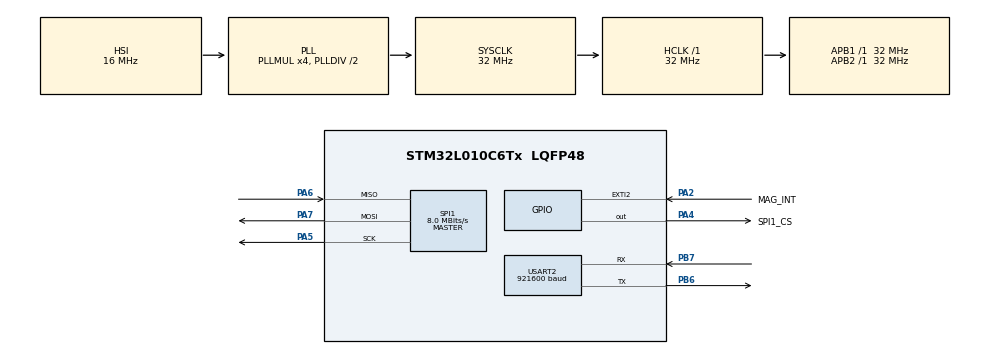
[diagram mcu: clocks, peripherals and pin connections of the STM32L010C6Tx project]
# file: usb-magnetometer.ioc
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Dma.Request0=USART2_RX
Dma.Request1=USART2_TX
Dma.USART2_RX.0.Direction=DMA_PERIPH_TO_MEMORY
Dma.USART2_RX.0.Instance=DMA1_Channel5
Dma.USART2_RX.0.MemDataAlignment=DMA_MDATAALIGN_BYTE
Dma.USART2_RX.0.MemInc=DMA_MINC_ENABLE
Dma.USART2_RX.0.Mode=DMA_NORMAL
Dma.USART2_RX.0.PeriphDataAlignment=DMA_PDATAALIGN_BYTE
Dma.USART2_RX.0.PeriphInc=DMA_PINC_DISABLE
Dma.USART2_RX.0.Priority=DMA_PRIORITY_MEDIUM
Dma.USART2_TX.1.Direction=DMA_MEMORY_TO_PERIPH
Dma.USART2_TX.1.Instance=DMA1_Channel4
Dma.USART2_TX.1.MemDataAlignment=DMA_MDATAALIGN_BYTE
Dma.USART2_TX.1.MemInc=DMA_MINC_ENABLE
Dma.USART2_TX.1.Mode=DMA_NORMAL
Dma.USART2_TX.1.PeriphDataAlignment=DMA_PDATAALIGN_BYTE
Dma.USART2_TX.1.PeriphInc=DMA_PINC_DISABLE
Dma.USART2_TX.1.Priority=DMA_PRIORITY_MEDIUM
Mcu.Family=STM32L0
Mcu.Name=STM32L010C6Tx
Mcu.Package=LQFP48
NVIC.DMA1_Channel4_5_6_7_IRQn=true\:0\:0\:false\:true\:true\:1\:false\:true\:true
NVIC.EXTI2_3_IRQn=true\:0\:0\:false\:true\:true\:3\:true\:true\:false
NVIC.USART2_IRQn=true\:0\:0\:false\:true\:true\:2\:true\:true\:true
PA2.GPIO_Label=MAG_INT
PA2.GPIO_ModeDefaultEXTI=GPIO_MODE_IT_FALLING
PA2.GPIO_PuPd=GPIO_NOPULL
PA2.Signal=GPXTI2
PA4.GPIO_Label=SPI1_CS
PA4.GPIO_Speed=GPIO_SPEED_FREQ_VERY_HIGH
PA4.PinState=GPIO_PIN_SET
PA4.Signal=GPIO_Output
PA5.Mode=Full_Duplex_Master
PA5.Signal=SPI1_SCK
PA6.Mode=Full_Duplex_Master
PA6.Signal=SPI1_MISO
PA7.Mode=Full_Duplex_Master
PA7.Signal=SPI1_MOSI
PB6.Mode=Asynchronous
PB6.Signal=USART2_TX
PB7.Mode=Asynchronous
PB7.Signal=USART2_RX
ProjectManager.HeapSize=0x000
ProjectManager.StackSize=0x200
ProjectManager.TargetToolchain=Makefile
RCC.AHBFreq_Value=32000000
RCC.APB1Freq_Value=32000000
RCC.APB1TimFreq_Value=32000000
RCC.APB2Freq_Value=32000000
RCC.APB2TimFreq_Value=32000000
RCC.HCLKFreq_Value=32000000
RCC.HSE_VALUE=24000000
RCC.HSI16_VALUE=16000000
RCC.HSI_VALUE=16000000
RCC.LSE_VALUE=32768
RCC.MSI_VALUE=2097000
RCC.PLLMUL=RCC_PLLMUL_4
RCC.SYSCLKFreq_VALUE=32000000
RCC.SYSCLKSource=RCC_SYSCLKSOURCE_PLLCLK
RCC.VCOOutputFreq_Value=64000000
SPI1.BaudRatePrescaler=SPI_BAUDRATEPRESCALER_4
SPI1.CRCCalculation=SPI_CRCCALCULATION_DISABLE
SPI1.CalculateBaudRate=8.0 MBits/s
SPI1.DataSize=SPI_DATASIZE_8BIT
SPI1.Direction=SPI_DIRECTION_2LINES
SPI1.Mode=SPI_MODE_MASTER
SPI1.TIMode=SPI_TIMODE_DISABLE
SPI1.VirtualType=VM_MASTER
USART2.BaudRate=921600
USART2.VirtualMode=VM_ASYNC
board=custom

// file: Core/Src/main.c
/* USER CODE BEGIN Header */
/**
  ******************************************************************************
  * @file           : main.c
  * @brief          : Main program body
  ******************************************************************************
  * @attention
  *
  * Copyright (c) 2023 STMicroelectronics.
  * All rights reserved.
  *
  * This software is licensed under terms that can be found in the LICENSE file
  * in the root directory of this software component.
  * If no LICENSE file comes with this software, it is provided AS-IS.
  *
  ******************************************************************************
  */
/* USER CODE END Header */
#include "main.h"
#include "dma.h"
#include "spi.h"
#include "usart.h"
#include "gpio.h"

/* USER CODE BEGIN Includes */
#include "server.h"
/* USER CODE END Includes */

void SystemClock_Config(void);
static void MX_NVIC_Init(void);

int main(void)
{

  /* MCU Configuration--------------------------------------------------------*/

  /* Reset of all peripherals, Initializes the Flash interface and the Systick. */
  HAL_Init();

  /* Configure the system clock */
  SystemClock_Config();

  /* Initialize all configured peripherals */
  MX_GPIO_Init();
  MX_DMA_Init();
  MX_SPI1_Init();
  MX_USART2_UART_Init();

  /* Initialize interrupts */
  MX_NVIC_Init();

  /* Infinite loop */
  /* USER CODE BEGIN WHILE */
  server_init();
  while (1)
  {
    server_run();
    sensor_run();
    /* USER CODE END WHILE */

  }
}

void SystemClock_Config(void)
{
  RCC_OscInitTypeDef RCC_OscInitStruct = {0};
  RCC_ClkInitTypeDef RCC_ClkInitStruct = {0};
  RCC_PeriphCLKInitTypeDef PeriphClkInit = {0};

  /** Configure the main internal regulator output voltage
  */
  __HAL_PWR_VOLTAGESCALING_CONFIG(PWR_REGULATOR_VOLTAGE_SCALE1);

  /** Initializes the RCC Oscillators according to the specified parameters
  * in the RCC_OscInitTypeDef structure.
  */
  RCC_OscInitStruct.OscillatorType = RCC_OSCILLATORTYPE_HSI;
  RCC_OscInitStruct.HSIState = RCC_HSI_ON;
  RCC_OscInitStruct.HSICalibrationValue = RCC_HSICALIBRATION_DEFAULT;
  RCC_OscInitStruct.PLL.PLLState = RCC_PLL_ON;
  RCC_OscInitStruct.PLL.PLLSource = RCC_PLLSOURCE_HSI;
  RCC_OscInitStruct.PLL.PLLMUL = RCC_PLLMUL_4;
  RCC_OscInitStruct.PLL.PLLDIV = RCC_PLLDIV_2;
  if (HAL_RCC_OscConfig(&RCC_OscInitStruct) != HAL_OK)
  {
    Error_Handler();
  }

  /** Initializes the CPU, AHB and APB buses clocks
  */
  RCC_ClkInitStruct.ClockType = RCC_CLOCKTYPE_HCLK|RCC_CLOCKTYPE_SYSCLK
                              |RCC_CLOCKTYPE_PCLK1|RCC_CLOCKTYPE_PCLK2;
  RCC_ClkInitStruct.SYSCLKSource = RCC_SYSCLKSOURCE_PLLCLK;
  RCC_ClkInitStruct.AHBCLKDivider = RCC_SYSCLK_DIV1;
  RCC_ClkInitStruct.APB1CLKDivider = RCC_HCLK_DIV1;
  RCC_ClkInitStruct.APB2CLKDivider = RCC_HCLK_DIV1;

  if (HAL_RCC_ClockConfig(&RCC_ClkInitStruct, FLASH_LATENCY_1) != HAL_OK)
  {
    Error_Handler();
  }
  PeriphClkInit.PeriphClockSelection = RCC_PERIPHCLK_USART2;
  PeriphClkInit.Usart2ClockSelection = RCC_USART2CLKSOURCE_PCLK1;
  if (HAL_RCCEx_PeriphCLKConfig(&PeriphClkInit) != HAL_OK)
  {
    Error_Handler();
  }
}

/**
  * @brief NVIC Configuration.
  * @retval None
  */
static void MX_NVIC_Init(void)
{
  /* DMA1_Channel4_5_6_7_IRQn interrupt configuration */
  HAL_NVIC_SetPriority(DMA1_Channel4_5_6_7_IRQn, 0, 0);
  HAL_NVIC_EnableIRQ(DMA1_Channel4_5_6_7_IRQn);
  /* USART2_IRQn interrupt configuration */
  HAL_NVIC_SetPriority(USART2_IRQn, 0, 0);
  HAL_NVIC_EnableIRQ(USART2_IRQn);
  /* EXTI2_3_IRQn interrupt configuration */
  HAL_NVIC_SetPriority(EXTI2_3_IRQn, 0, 0);
  HAL_NVIC_EnableIRQ(EXTI2_3_IRQn);
}

void Error_Handler(void)
{
  /* USER CODE BEGIN Error_Handler_Debug */
  /* User can add his own implementation to report the HAL error return state */
  __disable_irq();
  // HAL_NVIC_SystemReset();
  while (1)
  {
  }
  /* USER CODE END Error_Handler_Debug */
}
